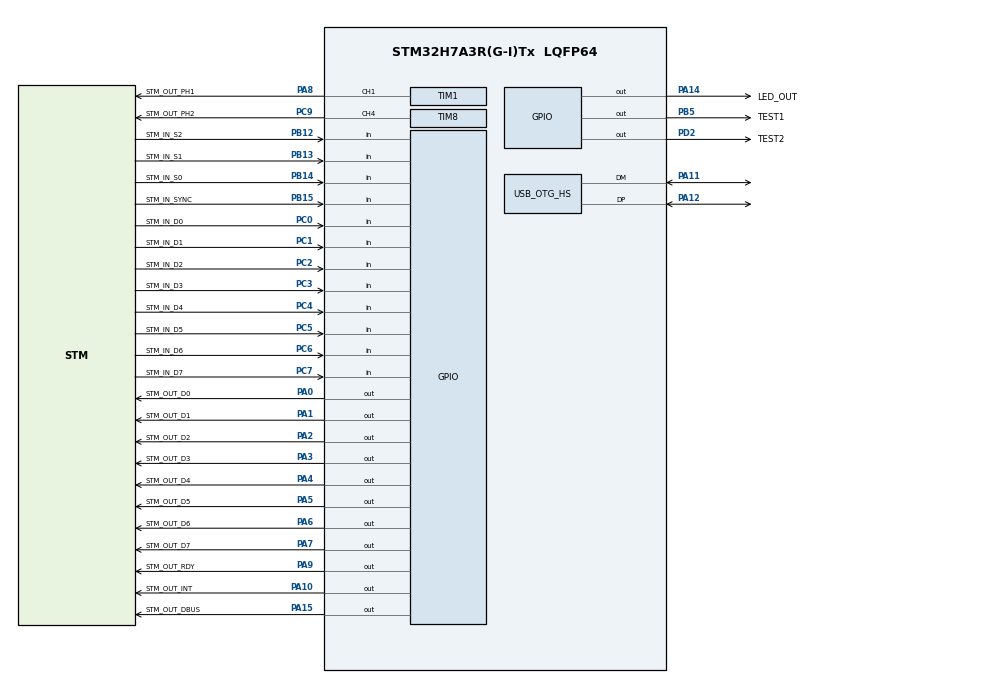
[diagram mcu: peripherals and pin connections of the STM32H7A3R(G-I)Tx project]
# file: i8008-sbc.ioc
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CORTEX_M7.default_mode_Activation=1
Mcu.Family=STM32H7
Mcu.Name=STM32H7A3R(G-I)Tx
Mcu.Package=LQFP64
NVIC.OTG_HS_IRQn=true\:0\:0\:false\:false\:true\:false\:true\:true
NVIC.PriorityGroup=NVIC_PRIORITYGROUP_4
PA0.GPIO_Label=STM_OUT_D0
PA0.Signal=GPIO_Output
PA1.GPIO_Label=STM_OUT_D1
PA1.Signal=GPIO_Output
PA10.GPIO_Label=STM_OUT_INT
PA10.Signal=GPIO_Output
PA11.Mode=Device_Only_FS
PA11.Signal=USB_OTG_HS_DM
PA12.Mode=Device_Only_FS
PA12.Signal=USB_OTG_HS_DP
PA14.GPIO_Label=LED_OUT
PA14.Signal=GPIO_Output
PA15.GPIO_Label=STM_OUT_DBUS
PA15.Signal=GPIO_Output
PA2.GPIO_Label=STM_OUT_D2
PA2.Signal=GPIO_Output
PA3.GPIO_Label=STM_OUT_D3
PA3.Signal=GPIO_Output
PA4.GPIO_Label=STM_OUT_D4
PA4.Signal=GPIO_Output
PA5.GPIO_Label=STM_OUT_D5
PA5.Signal=GPIO_Output
PA6.GPIO_Label=STM_OUT_D6
PA6.Signal=GPIO_Output
PA7.GPIO_Label=STM_OUT_D7
PA7.Signal=GPIO_Output
PA8.GPIO_Label=STM_OUT_PH1
PA8.Signal=S_TIM1_CH1
PA9.GPIO_Label=STM_OUT_RDY
PA9.Signal=GPIO_Output
PB12.GPIO_Label=STM_IN_S2
PB12.Signal=GPIO_Input
PB13.GPIO_Label=STM_IN_S1
PB13.Signal=GPIO_Input
PB14.GPIO_Label=STM_IN_S0
PB14.Signal=GPIO_Input
PB15.GPIO_Label=STM_IN_SYNC
PB15.Signal=GPIO_Input
PB5.GPIO_Label=TEST1
PB5.Signal=GPIO_Output
PC0.GPIO_Label=STM_IN_D0
PC0.Signal=GPIO_Input
PC1.GPIO_Label=STM_IN_D1
PC1.Signal=GPIO_Input
PC2.GPIO_Label=STM_IN_D2
PC2.Signal=GPIO_Input
PC3.GPIO_Label=STM_IN_D3
PC3.Signal=GPIO_Input
PC4.GPIO_Label=STM_IN_D4
PC4.Signal=GPIO_Input
PC5.GPIO_Label=STM_IN_D5
PC5.Signal=GPIO_Input
PC6.GPIO_Label=STM_IN_D6
PC6.Signal=GPIO_Input
PC7.GPIO_Label=STM_IN_D7
PC7.Signal=GPIO_Input
PC9.GPIO_Label=STM_OUT_PH2
PC9.Signal=S_TIM8_CH4
PD2.GPIO_Label=TEST2
PD2.Signal=GPIO_Output
PH0-OSC_IN.Mode=HSE-External-Oscillator
PH0-OSC_IN.Signal=RCC_OSC_IN
PH1-OSC_OUT.Mode=HSE-External-Oscillator
PH1-OSC_OUT.Signal=RCC_OSC_OUT
ProjectManager.HeapSize=0x200
ProjectManager.StackSize=0x400
ProjectManager.TargetToolchain=STM32CubeIDE
RCC.ADCFreq_Value=32250000
RCC.APB1Freq_Value=140000000
RCC.APB2Freq_Value=140000000
RCC.APB3Freq_Value=140000000
RCC.APB4Freq_Value=140000000
RCC.CDPPRE=RCC_APB3_DIV2
RCC.CDPPRE1=RCC_APB1_DIV2
RCC.CDPPRE2=RCC_APB2_DIV2
RCC.CortexFreq_Value=280000000
RCC.DIVM1=2
RCC.DIVM3=16
RCC.DIVN1=70
RCC.DIVN3=192
RCC.DIVQ1=3
RCC.DIVQ3=4
RCC.HCLKFreq_Value=280000000
RCC.HSE_VALUE=16000000
RCC.PLLFRACN=0
RCC.PLLSourceVirtual=RCC_PLLSOURCE_HSE
RCC.SRDPPRE=RCC_APB4_DIV2
RCC.SYSCLKFreq_VALUE=280000000
RCC.SYSCLKSource=RCC_SYSCLKSOURCE_PLLCLK
RCC.USBCLockSelection=RCC_USBCLKSOURCE_PLL3
RCC.USBFreq_Value=48000000
SH.S_TIM1_CH1.0=TIM1_CH1,PWM Generation1 CH1
SH.S_TIM8_CH4.0=TIM8_CH4,PWM Generation4 CH4
TIM1.Channel-Output\ Compare2\ No\ Output=TIM_CHANNEL_2
TIM1.Channel-PWM\ Generation1\ CH1=TIM_CHANNEL_1
TIM1.OCMode_2=TIM_OCMODE_ACTIVE
TIM1.Period=349
TIM1.Pulse-Output\ Compare2\ No\ Output=153
TIM1.Pulse-PWM\ Generation1\ CH1=97
TIM1.TIM_MasterOutputTrigger=TIM_TRGO_OC2REF
TIM1.TIM_MasterSlaveMode=TIM_MASTERSLAVEMODE_ENABLE
TIM8.Channel-PWM\ Generation4\ CH4=TIM_CHANNEL_4
TIM8.Period=349
TIM8.Pulse-PWM\ Generation4\ CH4=97
USB_DEVICE.CLASS_NAME_HS=CDC
USB_DEVICE.VirtualMode=Cdc
USB_DEVICE.VirtualMode-CDC_HS=Cdc
USB_DEVICE.VirtualModeHS=Cdc_HS
USB_OTG_HS.VirtualMode=Device_Only_FS
VP_TIM1_VS_ClockSourceINT.Mode=Internal
VP_TIM1_VS_no_output2.Mode=Output Compare2 No Output
VP_TIM8_VS_ClockSourceINT.Mode=Internal
VP_TIM8_VS_ClockSourceITR.Mode=TriggerSource_ITR0
VP_TIM8_VS_ControllerModeReset.Mode=Reset Mode
VP_USB_DEVICE_VS_USB_DEVICE_CDC_HS.Mode=CDC_HS
board=custom

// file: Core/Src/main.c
/* USER CODE BEGIN Header */
/**
  ******************************************************************************
  * @file           : main.c
  * @brief          : Main program body
  ******************************************************************************
  * @attention
  *
  * Copyright (c) 2023 STMicroelectronics.
  * All rights reserved.
  *
  * This software is licensed under terms that can be found in the LICENSE file
  * in the root directory of this software component.
  * If no LICENSE file comes with this software, it is provided AS-IS.
  *
  ******************************************************************************
  */
/* USER CODE END Header */
#include "main.h"
#include "tim.h"
#include "usb_device.h"
#include "gpio.h"

/* USER CODE BEGIN Includes */
#include "app.h"
/* USER CODE END Includes */

void SystemClock_Config(void);
static void MPU_Config(void);

int main(void)
{

  /* MPU Configuration--------------------------------------------------------*/
  MPU_Config();

  /* MCU Configuration--------------------------------------------------------*/

  /* Reset of all peripherals, Initializes the Flash interface and the Systick. */
  HAL_Init();

  /* Configure the system clock */
  SystemClock_Config();

  /* Initialize all configured peripherals */
  MX_GPIO_Init();
  MX_TIM1_Init();
  MX_TIM8_Init();
  MX_USB_DEVICE_Init();
  /* USER CODE BEGIN 2 */
  initApp();
  /* USER CODE END 2 */

  /* Infinite loop */
  while (1)
  {

    /* USER CODE BEGIN 3 */
    infiniteLoopIteration();
  }
  /* USER CODE END 3 */
}

void SystemClock_Config(void)
{
  RCC_OscInitTypeDef RCC_OscInitStruct = {0};
  RCC_ClkInitTypeDef RCC_ClkInitStruct = {0};

  /*AXI clock gating */
  RCC->CKGAENR = 0xFFFFFFFF;

  /** Supply configuration update enable
  */
  HAL_PWREx_ConfigSupply(PWR_LDO_SUPPLY);

  /** Configure the main internal regulator output voltage
  */
  __HAL_PWR_VOLTAGESCALING_CONFIG(PWR_REGULATOR_VOLTAGE_SCALE0);

  while(!__HAL_PWR_GET_FLAG(PWR_FLAG_VOSRDY)) {}

  /** Initializes the RCC Oscillators according to the specified parameters
  * in the RCC_OscInitTypeDef structure.
  */
  RCC_OscInitStruct.OscillatorType = RCC_OSCILLATORTYPE_HSE;
  RCC_OscInitStruct.HSEState = RCC_HSE_ON;
  RCC_OscInitStruct.PLL.PLLState = RCC_PLL_ON;
  RCC_OscInitStruct.PLL.PLLSource = RCC_PLLSOURCE_HSE;
  RCC_OscInitStruct.PLL.PLLM = 2;
  RCC_OscInitStruct.PLL.PLLN = 70;
  RCC_OscInitStruct.PLL.PLLP = 2;
  RCC_OscInitStruct.PLL.PLLQ = 3;
  RCC_OscInitStruct.PLL.PLLR = 2;
  RCC_OscInitStruct.PLL.PLLRGE = RCC_PLL1VCIRANGE_3;
  RCC_OscInitStruct.PLL.PLLVCOSEL = RCC_PLL1VCOWIDE;
  RCC_OscInitStruct.PLL.PLLFRACN = 0;
  if (HAL_RCC_OscConfig(&RCC_OscInitStruct) != HAL_OK)
  {
    Error_Handler();
  }

  /** Initializes the CPU, AHB and APB buses clocks
  */
  RCC_ClkInitStruct.ClockType = RCC_CLOCKTYPE_HCLK|RCC_CLOCKTYPE_SYSCLK
                              |RCC_CLOCKTYPE_PCLK1|RCC_CLOCKTYPE_PCLK2
                              |RCC_CLOCKTYPE_D3PCLK1|RCC_CLOCKTYPE_D1PCLK1;
  RCC_ClkInitStruct.SYSCLKSource = RCC_SYSCLKSOURCE_PLLCLK;
  RCC_ClkInitStruct.SYSCLKDivider = RCC_SYSCLK_DIV1;
  RCC_ClkInitStruct.AHBCLKDivider = RCC_HCLK_DIV1;
  RCC_ClkInitStruct.APB3CLKDivider = RCC_APB3_DIV2;
  RCC_ClkInitStruct.APB1CLKDivider = RCC_APB1_DIV2;
  RCC_ClkInitStruct.APB2CLKDivider = RCC_APB2_DIV2;
  RCC_ClkInitStruct.APB4CLKDivider = RCC_APB4_DIV2;

  if (HAL_RCC_ClockConfig(&RCC_ClkInitStruct, FLASH_LATENCY_6) != HAL_OK)
  {
    Error_Handler();
  }
}

/* MPU Configuration */

void MPU_Config(void)
{
  MPU_Region_InitTypeDef MPU_InitStruct = {0};

  /* Disables the MPU */
  HAL_MPU_Disable();

  /** Initializes and configures the Region and the memory to be protected
  */
  MPU_InitStruct.Enable = MPU_REGION_ENABLE;
  MPU_InitStruct.Number = MPU_REGION_NUMBER0;
  MPU_InitStruct.BaseAddress = 0x0;
  MPU_InitStruct.Size = MPU_REGION_SIZE_4GB;
  MPU_InitStruct.SubRegionDisable = 0x87;
  MPU_InitStruct.TypeExtField = MPU_TEX_LEVEL0;
  MPU_InitStruct.AccessPermission = MPU_REGION_NO_ACCESS;
  MPU_InitStruct.DisableExec = MPU_INSTRUCTION_ACCESS_DISABLE;
  MPU_InitStruct.IsShareable = MPU_ACCESS_SHAREABLE;
  MPU_InitStruct.IsCacheable = MPU_ACCESS_NOT_CACHEABLE;
  MPU_InitStruct.IsBufferable = MPU_ACCESS_NOT_BUFFERABLE;

  HAL_MPU_ConfigRegion(&MPU_InitStruct);
  /* Enables the MPU */
  HAL_MPU_Enable(MPU_PRIVILEGED_DEFAULT);

}

void Error_Handler(void)
{
  __disable_irq();
  while (1)
  {
  }
}
